# STM32F446 register map
File version: 1.1
CPU: CM4 r1p0, little endian, no MPU, no FPU, 3 interrupt priority bits
Registers are 32-bit, read-write, reset 0x0 unless marked. A register's access mark holds for its fields unless they carry their own. Offsets are from the block's base; [hi:lo] are bit positions; {n}, {i} and the like mark numbered series.

## SDMMC
Base 0x40012C00
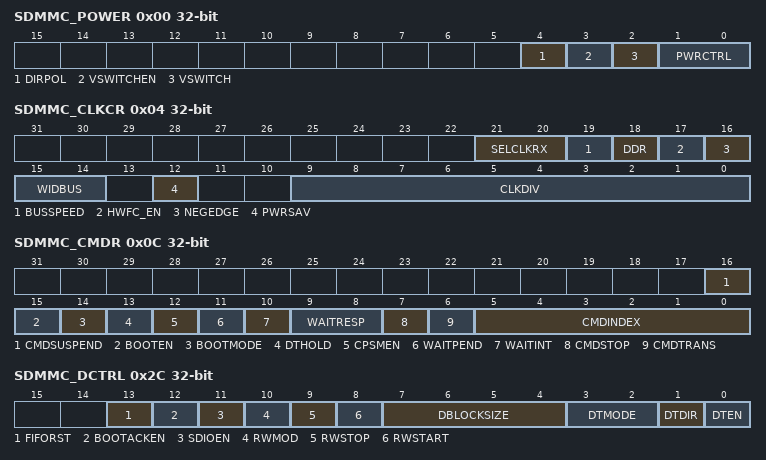
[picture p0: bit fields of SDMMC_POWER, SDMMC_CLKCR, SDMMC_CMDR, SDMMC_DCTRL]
0x00 SDMMC_POWER — SDMMC power control register
  [4] DIRPOL — Data and command direction signals polarity selection. This bit can only be written when the SDMMC is in the power-off state (PWRCTRL = 00).
  [3] VSWITCHEN — Voltage switch procedure enable. This bit can only be written by firmware when CPSM is disabled (CPSMEN = 0). This bit is used to stop the SDMMC_CK after the voltage switch command response:
  [2] VSWITCH — Voltage switch sequence start. This bit is used to start the timing critical section of the voltage switch sequence:
  [1:0] PWRCTRL — SDMMC state control bits. These bits can only be written when the SDMMC is not in the power-on state (PWRCTRL?11). These bits are used to define the functional state of the SDMMC signals: Any further write will be ignored, PWRCTRL value will keep 11.
0x04 SDMMC_CLKCR — The SDMMC_CLKCR register controls the SDMMC_CK output clock, the SDMMC_RX_CLK receive clock, and the bus width.
  [21:20] SELCLKRX — Receive clock selection. These bits can only be written when the CPSM and DPSM are not active (CPSMACT = 0 and DPSMACT = 0)
  [19] BUSSPEED — Bus speed mode selection between DS, HS, SDR12, SDR25 and SDR50, DDR50, SDR104. This bit can only be written when the CPSM and DPSM are not active (CPSMACT = 0 and DPSMACT = 0)
  [18] DDR — Data rate signaling selection This bit can only be written when the CPSM and DPSM are not active (CPSMACT = 0 and DPSMACT = 0) DDR rate shall only be selected with 4-bit or 8-bit wide bus mode. (WIDBUS > 00). DDR = 1 has no effect when WIDBUS = 00 (1-bit wide bus). DDR rate shall only be selected with clock division >1. (CLKDIV > 0)
  [17] HWFC_EN — Hardware flow control enable This bit can only be written when the CPSM and DPSM are not active (CPSMACT = 0 and DPSMACT = 0) When Hardware flow control is enabled, the meaning of the TXFIFOE and RXFIFOF flags change, please see SDMMC status register definition in Section56.8.11.
  [16] NEGEDGE — SDMMC_CK dephasing selection bit for data and Command. This bit can only be written when the CPSM and DPSM are not active (CPSMACT = 0 and DPSMACT = 0). When clock division = 1 (CLKDIV = 0), this bit has no effect. Data and Command change on SDMMC_CK falling edge. When clock division >1 (CLKDIV > 0) & DDR = 0: - SDMMC_CK edge occurs on SDMMCCLK rising edge. When clock division >1 (CLKDIV > 0) & DDR = 1: - Data changed on the SDMMCCLK falling edge succeeding a SDMMC_CK edge. - SDMMC_CK edge occurs on SDMMCCLK rising edge. - Data changed on the SDMMC_CK falling edge succeeding a SDMMC_CK edge. - SDMMC_CK edge occurs on SDMMCCLK rising edge.
  [15:14] WIDBUS — Wide bus mode enable bit This bit can only be written when the CPSM and DPSM are not active (CPSMACT = 0 and DPSMACT = 0)
  [12] PWRSAV — Power saving configuration bit This bit can only be written when the CPSM and DPSM are not active (CPSMACT = 0 and DPSMACT = 0) For power saving, the SDMMC_CK clock output can be disabled when the bus is idle by setting PWRSAV:
  [9:0] CLKDIV — Clock divide factor This bit can only be written when the CPSM and DPSM are not active (CPSMACT = 0 and DPSMACT = 0). This field defines the divide factor between the input clock (SDMMCCLK) and the output clock (SDMMC_CK): SDMMC_CK frequency = SDMMCCLK / [2 * CLKDIV]. 0xx: etc.. xxx: etc..
0x08 SDMMC_ARGR — The SDMMC_ARGR register contains a 32-bit command argument, which is sent to a card as part of a command message.
  [31:0] CMDARG — Command argument. These bits can only be written by firmware when CPSM is disabled (CPSMEN = 0). Command argument sent to a card as part of a command message. If a command contains an argument, it must be loaded into this register before writing a command to the command register.
0x0C SDMMC_CMDR — The SDMMC_CMDR register contains the command index and command type bits. The command index is sent to a card as part of a command message. The command type bits control the command path state machine (CPSM).
  [16] CMDSUSPEND — The CPSM treats the command as a Suspend or Resume command and signals interrupt period start/end. This bit can only be written by firmware when CPSM is disabled (CPSMEN = 0). CMDSUSPEND = 1 and CMDTRANS = 0 Suspend command, start interrupt period when response bit BS=0. CMDSUSPEND = 1 and CMDTRANS = 1 Resume command with data, end interrupt period when response bit DF=1.
  [15] BOOTEN — Enable boot mode procedure.
  [14] BOOTMODE — Select the boot mode procedure to be used. This bit can only be written by firmware when CPSM is disabled (CPSMEN = 0)
  [13] DTHOLD — Hold new data block transmission and reception in the DPSM. If this bit is set, the DPSM will not move from the Wait_S state to the Send state or from the Wait_R state to the Receive state.
  [12] CPSMEN — Command path state machine (CPSM) Enable bit This bit is written 1 by firmware, and cleared by hardware when the CPSM enters the Idle state. If this bit is set, the CPSM is enabled. When DTEN = 1, no command will be transfered nor boot procedure will be started. CPSMEN is cleared to 0.
  [11] WAITPEND — CPSM Waits for end of data transfer (CmdPend internal signal) from DPSM. This bit when set, the CPSM waits for the end of data transfer trigger before it starts sending a command. WAITPEND is only taken into account when DTMODE = MMC stream data transfer, WIDBUS = 1-bit wide bus mode, DPSMACT = 1 and DTDIR = from host to card.
  [10] WAITINT — CPSM waits for interrupt request. If this bit is set, the CPSM disables command timeout and waits for an card interrupt request (Response). If this bit is cleared in the CPSM Wait state, will cause the abort of the interrupt mode.
  [9:8] WAITRESP — Wait for response bits. This bit can only be written by firmware when CPSM is disabled (CPSMEN = 0). They are used to configure whether the CPSM is to wait for a response, and if yes, which kind of response.
  [7] CMDSTOP — The CPSM treats the command as a Stop Transmission command and signals Abort to the DPSM. This bit can only be written by firmware when CPSM is disabled (CPSMEN = 0). If this bit is set, the CPSM issues the Abort signal to the DPSM when the command is sent.
  [6] CMDTRANS — The CPSM treats the command as a data transfer command, stops the interrupt period, and signals DataEnable to the DPSM This bit can only be written by firmware when CPSM is disabled (CPSMEN = 0). If this bit is set, the CPSM issues an end of interrupt period and issues DataEnable signal to the DPSM when the command is sent.
  [5:0] CMDINDEX — Command index. This bit can only be written by firmware when CPSM is disabled (CPSMEN = 0). The command index is sent to the card as part of a command message.
{0xC+4i} SDMMC_RESP{i}R ro (i=1..4) — The SDMMC_RESP1/2/3/4R registers contain the status of a card, which is part of the received response.
  [31:0] CARDSTATUS{i} — see Table404.
0x24 SDMMC_DTIMER — The SDMMC_DTIMER register contains the data timeout period, in card bus clock periods. A counter loads the value from the SDMMC_DTIMER register, and starts decrementing when the data path state machine (DPSM) enters the Wait_R or Busy state. If the timer reaches 0 while the DPSM is in either of these states, the timeout status flag is set.
  [31:0] DATATIME — Data and R1b busy timeout period This bit can only be written when the CPSM and DPSM are not active (CPSMACT = 0 and DPSMACT = 0). Data and R1b busy timeout period expressed in card bus clock periods.
0x28 SDMMC_DLENR — The SDMMC_DLENR register contains the number of data bytes to be transferred. The value is loaded into the data counter when data transfer starts.
  [24:0] DATALENGTH — Data length value This register can only be written by firmware when DPSM is inactive (DPSMACT = 0). Number of data bytes to be transferred. When DDR = 1 DATALENGTH is truncated to a multiple of 2. (The last odd byte is not transfered) When DATALENGTH = 0 no data will be transfered, when requested by a CPSMEN and CMDTRANS = 1 also no command will be transfered. DTEN and CPSMEN are cleared to 0.
0x2C SDMMC_DCTRL — The SDMMC_DCTRL register control the data path state machine (DPSM).
  [13] FIFORST — FIFO reset, will flush any remaining data. This bit can only be written by firmware when IDMAEN= 0 and DPSM is active (DPSMACT = 1). This bit will only take effect when a transfer error or transfer hold occurs.
  [12] BOOTACKEN — Enable the reception of the boot acknowledgment. This bit can only be written by firmware when DPSM is inactive (DPSMACT = 0).
  [11] SDIOEN — SD I/O interrupt enable functions This bit can only be written by firmware when DPSM is inactive (DPSMACT = 0). If this bit is set, the DPSM enables the SD I/O card specific interrupt operation.
  [10] RWMOD — Read wait mode. This bit can only be written by firmware when DPSM is inactive (DPSMACT = 0).
  [9] RWSTOP — Read wait stop This bit is written by firmware and auto cleared by hardware when the DPSM moves from the READ_WAIT state to the WAIT_R or IDLE state.
  [8] RWSTART — Read wait start. If this bit is set, read wait operation starts.
  [7:4] DBLOCKSIZE — Data block size This bit can only be written by firmware when DPSM is inactive (DPSMACT = 0). Define the data block length when the block data transfer mode is selected: When DATALENGTH is not a multiple of DBLOCKSIZE, the transfered data is truncated at a multiple of DBLOCKSIZE. (Any remain data will not be transfered.) When DDR = 1, DBLOCKSIZE = 0000 shall not be used. (No data will be transfered)
  [3:2] DTMODE — Data transfer mode selection. This bit can only be written by firmware when DPSM is inactive (DPSMACT = 0).
  [1] DTDIR — Data transfer direction selection This bit can only be written by firmware when DPSM is inactive (DPSMACT = 0).
  [0] DTEN — Data transfer enable bit This bit can only be written by firmware when DPSM is inactive (DPSMACT = 0). This bit is cleared by Hardware when data transfer completes. This bit shall only be used to transfer data when no associated data transfer command is used, i.e. shall not be used with SD or eMMC cards.
0x30 SDMMC_DCNTR ro — The SDMMC_DCNTR register loads the value from the data length register (see SDMMC_DLENR) when the DPSM moves from the Idle state to the Wait_R or Wait_S state. As data is transferred, the counter decrements the value until it reaches 0. The DPSM then moves to the Idle state and when there has been no error, the data status end flag (DATAEND) is set.
  [26:0] DATACOUNT — Data count value When read, the number of remaining data bytes to be transferred is returned. Write has no effect.
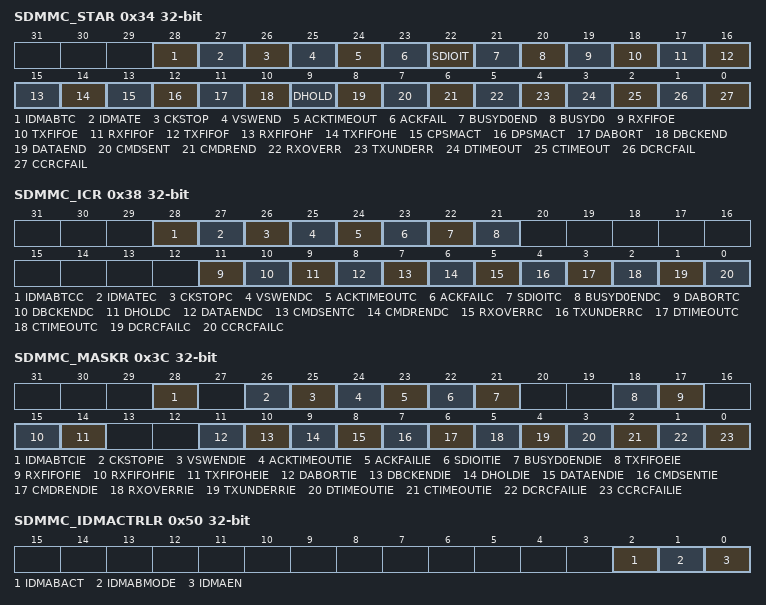
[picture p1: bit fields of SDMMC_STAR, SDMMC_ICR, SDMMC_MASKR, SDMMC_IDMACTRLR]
0x34 SDMMC_STAR ro — The SDMMC_STAR register is a read-only register. It contains two types of flag:Static flags (bits [29,21,11:0]): these bits remain asserted until they are cleared by writing to the SDMMC interrupt Clear register (see SDMMC_ICR)Dynamic flags (bits [20:12]): these bits change state depending on the state of the underlying logic (for example, FIFO full and empty flags are asserted and de-asserted as data while written to the FIFO)
  [28] IDMABTC — IDMA buffer transfer complete. interrupt flag is cleared by writing corresponding interrupt clear bit in SDMMC_ICR.
  [27] IDMATE — IDMA transfer error. Interrupt flag is cleared by writing corresponding interrupt clear bit in SDMMC_ICR.
  [26] CKSTOP — SDMMC_CK stopped in Voltage switch procedure. Interrupt flag is cleared by writing corresponding interrupt clear bit in SDMMC_ICR.
  [25] VSWEND — Voltage switch critical timing section completion. Interrupt flag is cleared by writing corresponding interrupt clear bit in SDMMC_ICR.
  [24] ACKTIMEOUT — Boot acknowledgment timeout. Interrupt flag is cleared by writing corresponding interrupt clear bit in SDMMC_ICR.
  [23] ACKFAIL — Boot acknowledgment received (boot acknowledgment check fail). Interrupt flag is cleared by writing corresponding interrupt clear bit in SDMMC_ICR.
  [22] SDIOIT — SDIO interrupt received. Interrupt flag is cleared by writing corresponding interrupt clear bit in SDMMC_ICR.
  [21] BUSYD0END — end of SDMMC_D0 Busy following a CMD response detected. This indicates only end of busy following a CMD response. This bit does not signal busy due to data transfer. Interrupt flag is cleared by writing corresponding interrupt clear bit in SDMMC_ICR.
  [20] BUSYD0 — Inverted value of SDMMC_D0 line (Busy), sampled at the end of a CMD response and a second time 2 SDMMC_CK cycles after the CMD response. This bit is reset to not busy when the SDMMCD0 line changes from busy to not busy. This bit does not signal busy due to data transfer. This is a hardware status flag only, it does not generate an interrupt.
  [19] RXFIFOE — Receive FIFO empty This is a hardware status flag only, does not generate an interrupt. This bit is cleared when one FIFO location becomes full.
  [18] TXFIFOE — Transmit FIFO empty This bit is cleared when one FIFO location becomes full.
  [17] RXFIFOF — Receive FIFO full This bit is cleared when one FIFO location becomes empty.
  [16] TXFIFOF — Transmit FIFO full This is a hardware status flag only, does not generate an interrupt. This bit is cleared when one FIFO location becomes empty.
  [15] RXFIFOHF — Receive FIFO half full There are at least half the number of words in the FIFO. This bit is cleared when the FIFO becomes half+1 empty.
  [14] TXFIFOHE — Transmit FIFO half empty At least half the number of words can be written into the FIFO. This bit is cleared when the FIFO becomes half+1 full.
  [13] CPSMACT — Command path state machine active, i.e. not in Idle state. This is a hardware status flag only, does not generate an interrupt.
  [12] DPSMACT — Data path state machine active, i.e. not in Idle state. This is a hardware status flag only, does not generate an interrupt.
  [11] DABORT — Data transfer aborted by CMD12. Interrupt flag is cleared by writing corresponding interrupt clear bit in SDMMC_ICR.
  [10] DBCKEND — Data block sent/received. (CRC check passed) and DPSM moves to the READWAIT state. Interrupt flag is cleared by writing corresponding interrupt clear bit in SDMMC_ICR.
  [9] DHOLD — Data transfer Hold. Interrupt flag is cleared by writing corresponding interrupt clear bit in SDMMC_ICR.
  [8] DATAEND — Data transfer ended correctly. (data counter, DATACOUNT is zero and no errors occur). Interrupt flag is cleared by writing corresponding interrupt clear bit in SDMMC_ICR.
  [7] CMDSENT — Command sent (no response required). Interrupt flag is cleared by writing corresponding interrupt clear bit in SDMMC_ICR.
  [6] CMDREND — Command response received (CRC check passed, or no CRC). Interrupt flag is cleared by writing corresponding interrupt clear bit in SDMMC_ICR.
  [5] RXOVERR — Received FIFO overrun error or IDMA write transfer error. Interrupt flag is cleared by writing corresponding interrupt clear bit in SDMMC_ICR.
  [4] TXUNDERR — Transmit FIFO underrun error or IDMA read transfer error. Interrupt flag is cleared by writing corresponding interrupt clear bit in SDMMC_ICR.
  [3] DTIMEOUT — Data timeout. Interrupt flag is cleared by writing corresponding interrupt clear bit in SDMMC_ICR.
  [2] CTIMEOUT — Command response timeout. Interrupt flag is cleared by writing corresponding interrupt clear bit in SDMMC_ICR. The Command Timeout period has a fixed value of 64 SDMMC_CK clock periods.
  [1] DCRCFAIL — Data block sent/received (CRC check failed). Interrupt flag is cleared by writing corresponding interrupt clear bit in SDMMC_ICR.
  [0] CCRCFAIL — Command response received (CRC check failed). Interrupt flag is cleared by writing corresponding interrupt clear bit in SDMMC_ICR.
0x38 SDMMC_ICR — The SDMMC_ICR register is a write-only register. Writing a bit with 1 clears the corresponding bit in the SDMMC_STAR status register.
  [28] IDMABTCC — IDMA buffer transfer complete clear bit Set by software to clear the IDMABTC flag.
  [27] IDMATEC — IDMA transfer error clear bit Set by software to clear the IDMATE flag.
  [26] CKSTOPC — CKSTOP flag clear bit Set by software to clear the CKSTOP flag.
  [25] VSWENDC — VSWEND flag clear bit Set by software to clear the VSWEND flag.
  [24] ACKTIMEOUTC — ACKTIMEOUT flag clear bit Set by software to clear the ACKTIMEOUT flag.
  [23] ACKFAILC — ACKFAIL flag clear bit Set by software to clear the ACKFAIL flag.
  [22] SDIOITC — SDIOIT flag clear bit Set by software to clear the SDIOIT flag.
  [21] BUSYD0ENDC — BUSYD0END flag clear bit Set by software to clear the BUSYD0END flag.
  [11] DABORTC — DABORT flag clear bit Set by software to clear the DABORT flag.
  [10] DBCKENDC — DBCKEND flag clear bit Set by software to clear the DBCKEND flag.
  [9] DHOLDC — DHOLD flag clear bit Set by software to clear the DHOLD flag.
  [8] DATAENDC — DATAEND flag clear bit Set by software to clear the DATAEND flag.
  [7] CMDSENTC — CMDSENT flag clear bit Set by software to clear the CMDSENT flag.
  [6] CMDRENDC — CMDREND flag clear bit Set by software to clear the CMDREND flag.
  [5] RXOVERRC — RXOVERR flag clear bit Set by software to clear the RXOVERR flag.
  [4] TXUNDERRC — TXUNDERR flag clear bit Set by software to clear TXUNDERR flag.
  [3] DTIMEOUTC — DTIMEOUT flag clear bit Set by software to clear the DTIMEOUT flag.
  [2] CTIMEOUTC — CTIMEOUT flag clear bit Set by software to clear the CTIMEOUT flag.
  [1] DCRCFAILC — DCRCFAIL flag clear bit Set by software to clear the DCRCFAIL flag.
  [0] CCRCFAILC — CCRCFAIL flag clear bit Set by software to clear the CCRCFAIL flag.
0x3C SDMMC_MASKR — The interrupt mask register determines which status flags generate an interrupt request by setting the corresponding bit to 1.
  [28] IDMABTCIE — IDMA buffer transfer complete interrupt enable Set and cleared by software to enable/disable the interrupt generated when the IDMA has transferred all data belonging to a memory buffer.
  [26] CKSTOPIE — Voltage Switch clock stopped interrupt enable Set and cleared by software to enable/disable interrupt caused by Voltage Switch clock stopped.
  [25] VSWENDIE — Voltage switch critical timing section completion interrupt enable Set and cleared by software to enable/disable the interrupt generated when voltage switch critical timing section completion.
  [24] ACKTIMEOUTIE — Acknowledgment timeout interrupt enable Set and cleared by software to enable/disable interrupt caused by acknowledgment timeout.
  [23] ACKFAILIE — Acknowledgment Fail interrupt enable Set and cleared by software to enable/disable interrupt caused by acknowledgment Fail.
  [22] SDIOITIE — SDIO mode interrupt received interrupt enable Set and cleared by software to enable/disable the interrupt generated when receiving the SDIO mode interrupt.
  [21] BUSYD0ENDIE — BUSYD0END interrupt enable Set and cleared by software to enable/disable the interrupt generated when SDMMC_D0 signal changes from busy to NOT busy following a CMD response.
  [18] TXFIFOEIE — Tx FIFO empty interrupt enable Set and cleared by software to enable/disable interrupt caused by Tx FIFO empty.
  [17] RXFIFOFIE — Rx FIFO full interrupt enable Set and cleared by software to enable/disable interrupt caused by Rx FIFO full.
  [15] RXFIFOHFIE — Rx FIFO half full interrupt enable Set and cleared by software to enable/disable interrupt caused by Rx FIFO half full.
  [14] TXFIFOHEIE — Tx FIFO half empty interrupt enable Set and cleared by software to enable/disable interrupt caused by Tx FIFO half empty.
  [11] DABORTIE — Data transfer aborted interrupt enable Set and cleared by software to enable/disable interrupt caused by a data transfer being aborted.
  [10] DBCKENDIE — Data block end interrupt enable Set and cleared by software to enable/disable interrupt caused by data block end.
  [9] DHOLDIE — Data hold interrupt enable Set and cleared by software to enable/disable the interrupt generated when sending new data is hold in the DPSM Wait_S state.
  [8] DATAENDIE — Data end interrupt enable Set and cleared by software to enable/disable interrupt caused by data end.
  [7] CMDSENTIE — Command sent interrupt enable Set and cleared by software to enable/disable interrupt caused by sending command.
  [6] CMDRENDIE — Command response received interrupt enable Set and cleared by software to enable/disable interrupt caused by receiving command response.
  [5] RXOVERRIE — Rx FIFO overrun error interrupt enable Set and cleared by software to enable/disable interrupt caused by Rx FIFO overrun error.
  [4] TXUNDERRIE — Tx FIFO underrun error interrupt enable Set and cleared by software to enable/disable interrupt caused by Tx FIFO underrun error.
  [3] DTIMEOUTIE — Data timeout interrupt enable Set and cleared by software to enable/disable interrupt caused by data timeout.
  [2] CTIMEOUTIE — Command timeout interrupt enable Set and cleared by software to enable/disable interrupt caused by command timeout.
  [1] DCRCFAILIE — Data CRC fail interrupt enable Set and cleared by software to enable/disable interrupt caused by data CRC failure.
  [0] CCRCFAILIE — Command CRC fail interrupt enable Set and cleared by software to enable/disable interrupt caused by command CRC failure.
0x40 SDMMC_ACKTIMER — The SDMMC_ACKTIMER register contains the acknowledgment timeout period, in SDMMC_CK bus clock periods. A counter loads the value from the SDMMC_ACKTIMER register, and starts decrementing when the data path state machine (DPSM) enters the Wait_Ack state. If the timer reaches 0 while the DPSM is in this states, the acknowledgment timeout status flag is set.
  [24:0] ACKTIME — Boot acknowledgment timeout period This bit can only be written by firmware when CPSM is disabled (CPSMEN = 0). Boot acknowledgment timeout period expressed in card bus clock periods.
0x50 SDMMC_IDMACTRLR — The receive and transmit FIFOs can be read or written as 32-bit wide registers. The FIFOs contain 32 entries on 32 sequential addresses. This allows the CPU to use its load and store multiple operands to read from/write to the FIFO.
  [2] IDMABACT — Double buffer mode active buffer indication This bit can only be written by firmware when DPSM is inactive (DPSMACT = 0). When IDMA is enabled this bit is toggled by hardware.
  [1] IDMABMODE — Buffer mode selection. This bit can only be written by firmware when DPSM is inactive (DPSMACT = 0).
  [0] IDMAEN — IDMA enable This bit can only be written by firmware when DPSM is inactive (DPSMACT = 0).
0x54 SDMMC_IDMABSIZER — The SDMMC_IDMABSIZER register contains the buffers size when in double buffer configuration.
  [12:5] IDMABNDT — Number of transfers per buffer. This 8-bit value shall be multiplied by 8 to get the size of the buffer in 32-bit words and by 32 to get the size of the buffer in bytes. Example: IDMABNDT = 0x01: buffer size = 8 words = 32 bytes. These bits can only be written by firmware when DPSM is inactive (DPSMACT = 0).
0x58 SDMMC_IDMABASE0R — The SDMMC_IDMABASE0R register contains the memory buffer base address in single buffer configuration and the buffer 0 base address in double buffer configuration.
  [31:0] IDMABASE0 — Buffer 0 memory base address bits [31:2], shall be word aligned (bit [1:0] are always 0 and read only). This register can be written by firmware when DPSM is inactive (DPSMACT = 0), and can dynamically be written by firmware when DPSM active (DPSMACT = 1) and memory buffer 0 is inactive (IDMABACT = 1).
0x5C SDMMC_IDMABASE1R — The SDMMC_IDMABASE1R register contains the double buffer configuration second buffer memory base address.
  [31:0] IDMABASE1 — Buffer 1 memory base address, shall be word aligned (bit [1:0] are always 0 and read only). This register can be written by firmware when DPSM is inactive (DPSMACT = 0), and can dynamically be written by firmware when DPSM active (DPSMACT = 1) and memory buffer 1 is inactive (IDMABACT = 0).
0x60 SDMMC_RESPCMDR ro — The SDMMC_RESPCMDR register contains the command index field of the last command response received. If the command response transmission does not contain the command index field (long or OCR response), the RESPCMD field is unknown, although it must contain 111111b (the value of the reserved field from the response).
  [5:0] RESPCMD — Response command index Read-only bit field. Contains the command index of the last command response received.
0x80 SDMMC_FIFOR — The receive and transmit FIFOs can be only read or written as word (32-bit) wide registers. The FIFOs contain 16 entries on sequential addresses. This allows the CPU to use its load and store multiple operands to read from/write to the FIFO.When accessing SDMMC_FIFOR with half word or byte access an AHB bus fault is generated.
  [31:0] FIFODATA — Receive and transmit FIFO data This register can only be read or written by firmware when the DPSM is active (DPSMACT=1). The FIFO data occupies 16 entries of 32-bit words.
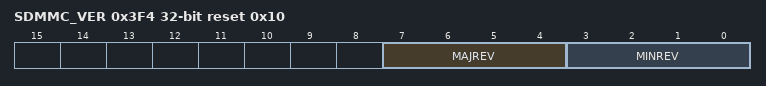
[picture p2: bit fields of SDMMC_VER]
0x3F4 SDMMC_VER ro reset 0x10 — SDMMC IP version register
  [7:4] MAJREV — IP major revision number.
  [3:0] MINREV — IP minor revision number.
0x3F8 SDMMC_ID ro reset 0x140022 — SDMMC IP identification register
  [31:0] IP_ID — SDMMC IP identification.
